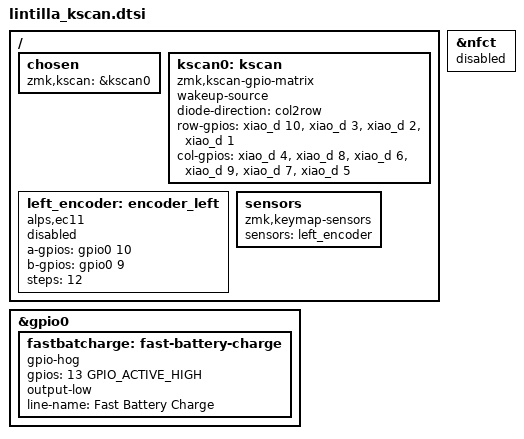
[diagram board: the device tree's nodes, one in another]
/ {
    chosen {
        zmk,kscan = &kscan0;
    };

    kscan0: kscan {
        compatible = "zmk,kscan-gpio-matrix";
        wakeup-source;
        diode-direction = "col2row";

        row-gpios
            = <&xiao_d 10 (GPIO_ACTIVE_HIGH | GPIO_PULL_DOWN)>
            , <&xiao_d 3 (GPIO_ACTIVE_HIGH | GPIO_PULL_DOWN)>
            , <&xiao_d 2 (GPIO_ACTIVE_HIGH | GPIO_PULL_DOWN)>
            , <&xiao_d 1 (GPIO_ACTIVE_HIGH | GPIO_PULL_DOWN)>
            ;

        col-gpios
            = <&xiao_d 4 GPIO_ACTIVE_HIGH>
            , <&xiao_d 8 GPIO_ACTIVE_HIGH>
            , <&xiao_d 6 GPIO_ACTIVE_HIGH>
            , <&xiao_d 9 GPIO_ACTIVE_HIGH>
            , <&xiao_d 7 GPIO_ACTIVE_HIGH>
            , <&xiao_d 5 GPIO_ACTIVE_HIGH>
            ;
    };
    left_encoder: encoder_left {
        compatible = "alps,ec11";
        a-gpios = <&gpio0 10 (GPIO_ACTIVE_HIGH | GPIO_PULL_UP)>;
        b-gpios = <&gpio0 9 (GPIO_ACTIVE_HIGH | GPIO_PULL_UP)>;
        steps = <12>;
        status = "disabled";
    };

    sensors: sensors {
        compatible = "zmk,keymap-sensors";
        sensors = <&left_encoder>;
//        triggers-per-rotation = <10>;
    };
};

// Disable NFC
&nfct {
    status = "disabled";
};

// For bigger batteries, we want to enable faster charging
&gpio0 {
    fastbatcharge: fast-battery-charge {
        gpio-hog;
        gpios = <13 GPIO_ACTIVE_HIGH>;
        output-low;
        line-name = "Fast Battery Charge";
    };
};

// vim: expandtab softtabstop=4 shiftwidth=4
